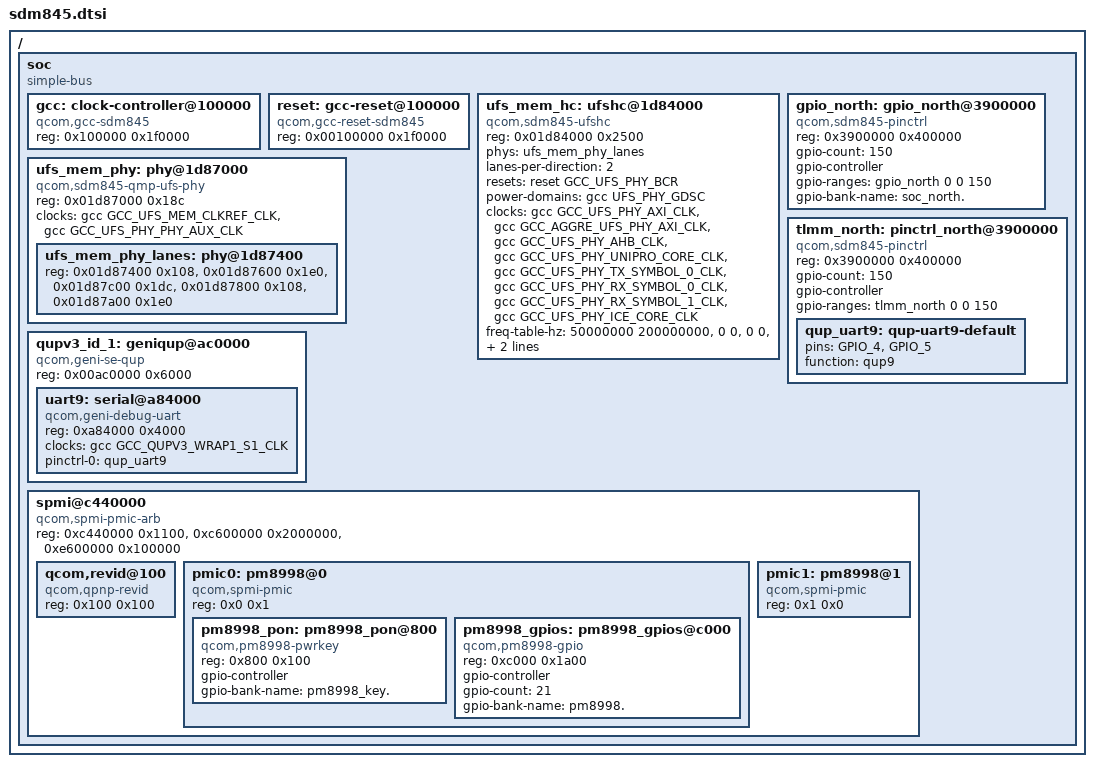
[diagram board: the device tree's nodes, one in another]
// SPDX-License-Identifier: GPL-2.0+
/*
 * Qualcomm SDM845 chip device tree source
 *
 * (C) Copyright 2021 Dzmitry Sankouski <dsankouski@gmail.com>
 *
 */

/dts-v1/;

#include <dt-bindings/clock/qcom,gcc-sdm845.h>
#include "skeleton64.dtsi"

/ {
	soc: soc {
		#address-cells = <1>;
		#size-cells = <1>;
		ranges = <0 0 0 0xffffffff>;
		compatible = "simple-bus";

		gcc: clock-controller@100000 {
			compatible = "qcom,gcc-sdm845";
			reg = <0x100000 0x1f0000>;
			#clock-cells = <1>;
			#reset-cells = <1>;
			#power-domain-cells = <1>;
		};

		reset: gcc-reset@100000 {
			compatible = "qcom,gcc-reset-sdm845";
			reg = <0x00100000 0x1f0000>;
			#reset-cells = <1>;
		};

		ufs_mem_hc: ufshc@1d84000 {
			compatible = "qcom,sdm845-ufshc", "qcom,ufshc",
				     "jedec,ufs-2.0";
			reg = <0x01d84000 0x2500>;
			phys = <&ufs_mem_phy_lanes>;
			phy-names = "ufsphy";
			lanes-per-direction = <2>;
			#reset-cells = <1>;
			resets = <&reset GCC_UFS_PHY_BCR>;
			reset-names = "rst";

			power-domains = <&gcc UFS_PHY_GDSC>;

			clock-names =
				"core_clk",
				"bus_aggr_clk",
				"iface_clk",
				"core_clk_unipro",
				"tx_lane0_sync_clk",
				"rx_lane0_sync_clk",
				"rx_lane1_sync_clk",
				"ice_core_clk";
			clocks =
				<&gcc GCC_UFS_PHY_AXI_CLK>,
				<&gcc GCC_AGGRE_UFS_PHY_AXI_CLK>,
				<&gcc GCC_UFS_PHY_AHB_CLK>,
				<&gcc GCC_UFS_PHY_UNIPRO_CORE_CLK>,
				<&gcc GCC_UFS_PHY_TX_SYMBOL_0_CLK>,
				<&gcc GCC_UFS_PHY_RX_SYMBOL_0_CLK>,
				<&gcc GCC_UFS_PHY_RX_SYMBOL_1_CLK>,
				<&gcc GCC_UFS_PHY_ICE_CORE_CLK>;
			freq-table-hz =
				<50000000 200000000>,
				<0 0>,
				<0 0>,
				<37500000 150000000>,
				<0 0>,
				<0 0>,
				<0 0>,
				<0 300000000>;
		};

		ufs_mem_phy: phy@1d87000 {
			compatible = "qcom,sdm845-qmp-ufs-phy";
			reg = <0x01d87000 0x18c>;
			#address-cells = <1>;
			#size-cells = <1>;
			ranges;
			clock-names = "ref",
				      "ref_aux";
			clocks = <&gcc GCC_UFS_MEM_CLKREF_CLK>,
				 <&gcc GCC_UFS_PHY_PHY_AUX_CLK>;

			ufs_mem_phy_lanes: phy@1d87400 {
				reg = <0x01d87400 0x108>,
				      <0x01d87600 0x1e0>,
				      <0x01d87c00 0x1dc>,
				      <0x01d87800 0x108>,
				      <0x01d87a00 0x1e0>;
				#phy-cells = <0>;
			};
		};

		gpio_north: gpio_north@3900000 {
			#gpio-cells = <2>;
			compatible = "qcom,sdm845-pinctrl";
			reg = <0x3900000 0x400000>;
			gpio-count = <150>;
			gpio-controller;
			gpio-ranges = <&gpio_north 0 0 150>;
			gpio-bank-name = "soc_north.";
		};

		tlmm_north: pinctrl_north@3900000 {
			compatible = "qcom,sdm845-pinctrl";
			reg = <0x3900000 0x400000>;
			gpio-count = <150>;
			gpio-controller;
			#gpio-cells = <2>;
			gpio-ranges = <&tlmm_north 0 0 150>;

			/* DEBUG UART */
			qup_uart9: qup-uart9-default {
				pins = "GPIO_4", "GPIO_5";
				function = "qup9";
			};
		};

		qupv3_id_1: geniqup@ac0000 {
			compatible = "qcom,geni-se-qup";
			reg = <0x00ac0000 0x6000>;
			#address-cells = <1>;
			#size-cells = <1>;
			ranges;

			uart9: serial@a84000 {
				compatible = "qcom,geni-debug-uart";
				reg = <0xa84000 0x4000>;
				clock-names = "se";
				clocks = <&gcc GCC_QUPV3_WRAP1_S1_CLK>;
				pinctrl-names = "default";
				pinctrl-0 = <&qup_uart9>;
			};
		};

		spmi@c440000 {
			compatible = "qcom,spmi-pmic-arb";
			reg = <0xc440000 0x1100>,
			      <0xc600000 0x2000000>,
			      <0xe600000 0x100000>;
			reg-names = "cnfg", "core", "obsrvr";
			#address-cells = <0x1>;
			#size-cells = <0x1>;

			qcom,revid@100 {
				compatible = "qcom,qpnp-revid";
				reg = <0x100 0x100>;
			};

			pmic0: pm8998@0 {
				compatible = "qcom,spmi-pmic";
				reg = <0x0 0x1>;
				#address-cells = <0x1>;
				#size-cells = <0x1>;

				pm8998_pon: pm8998_pon@800 {
					compatible = "qcom,pm8998-pwrkey";
					reg = <0x800 0x100>;
					#gpio-cells = <2>;
					gpio-controller;
					gpio-bank-name = "pm8998_key.";
				};

				pm8998_gpios: pm8998_gpios@c000 {
					compatible = "qcom,pm8998-gpio";
					reg = <0xc000 0x1a00>;
					gpio-controller;
					gpio-count = <21>;
					#gpio-cells = <2>;
					gpio-bank-name = "pm8998.";
				};
			};

			pmic1: pm8998@1 {
				compatible = "qcom,spmi-pmic";
				reg = <0x1 0x0>;
				#address-cells = <0x2>;
				#size-cells = <0x0>;
			};
		};
	};
};
